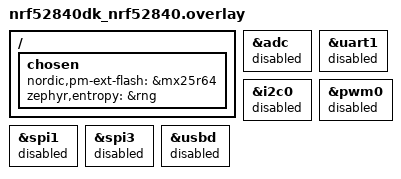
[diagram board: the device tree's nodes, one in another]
/*
 *    Copyright (c) 2020 Project CHIP Authors
 *
 *    Licensed under the Apache License, Version 2.0 (the "License");
 *    you may not use this file except in compliance with the License.
 *    You may obtain a copy of the License at
 *
 *        http://www.apache.org/licenses/LICENSE-2.0
 *
 *    Unless required by applicable law or agreed to in writing, software
 *    distributed under the License is distributed on an "AS IS" BASIS,
 *    WITHOUT WARRANTIES OR CONDITIONS OF ANY KIND, either express or implied.
 *    See the License for the specific language governing permissions and
 *    limitations under the License.
 */

/ {
	chosen {
		nordic,pm-ext-flash = &mx25r64;
	};

	/*
	* In some default configurations within the nRF Connect SDK,
	* e.g. on nRF52840, the chosen zephyr,entropy node is &cryptocell.
	* This devicetree overlay ensures that default is overridden wherever it
	* is set, as this application uses the RNG node for entropy exclusively.
	*/
	chosen {
		zephyr,entropy = &rng;
	};
};

/* Disable unused peripherals to reduce power consumption */
&adc {
	status = "disabled";
};
&uart1 {
	status = "disabled";
};
&i2c0 {
	status = "disabled";
};
&pwm0 {
	status = "disabled";
};
&spi1 {
	status = "disabled";
};
&spi3 {
	status = "disabled";
};
&usbd {
	status = "disabled";
};
